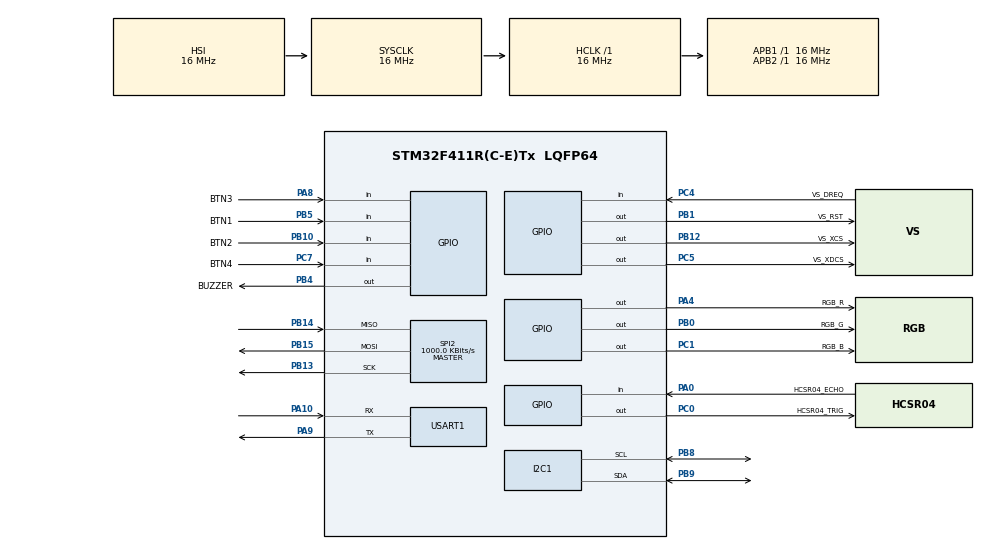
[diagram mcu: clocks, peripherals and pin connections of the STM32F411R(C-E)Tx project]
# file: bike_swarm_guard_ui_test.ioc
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Mcu.Family=STM32F4
Mcu.Name=STM32F411R(C-E)Tx
Mcu.Package=LQFP64
NVIC.PriorityGroup=NVIC_PRIORITYGROUP_4
NVIC.USART1_IRQn=true\:0\:0\:false\:false\:true\:true\:true\:true
PA0-WKUP.GPIO_Label=HCSR04_ECHO
PA0-WKUP.GPIO_PuPd=GPIO_PULLDOWN
PA0-WKUP.Signal=GPIO_Input
PA10.Mode=Asynchronous
PA10.Signal=USART1_RX
PA4.GPIO_Label=RGB_R
PA4.Signal=GPIO_Output
PA8.GPIO_Label=BTN3
PA8.GPIO_PuPd=GPIO_PULLUP
PA8.Signal=GPIO_Input
PA9.Mode=Asynchronous
PA9.Signal=USART1_TX
PB0.GPIO_Label=RGB_G
PB0.Signal=GPIO_Output
PB1.GPIO_Label=VS_RST
PB1.PinState=GPIO_PIN_SET
PB1.Signal=GPIO_Output
PB10.GPIO_Label=BTN2
PB10.GPIO_PuPd=GPIO_PULLUP
PB10.Signal=GPIO_Input
PB12.GPIO_Label=VS_XCS
PB12.PinState=GPIO_PIN_SET
PB12.Signal=GPIO_Output
PB13.Mode=Full_Duplex_Master
PB13.Signal=SPI2_SCK
PB14.Mode=Full_Duplex_Master
PB14.Signal=SPI2_MISO
PB15.Mode=Full_Duplex_Master
PB15.Signal=SPI2_MOSI
PB4.GPIO_Label=BUZZER
PB4.Signal=GPIO_Output
PB5.GPIO_Label=BTN1
PB5.GPIO_PuPd=GPIO_PULLUP
PB5.Signal=GPIO_Input
PB8.GPIO_Pu=GPIO_PULLUP
PB8.Mode=I2C
PB8.Signal=I2C1_SCL
PB9.GPIO_Pu=GPIO_PULLUP
PB9.Mode=I2C
PB9.Signal=I2C1_SDA
PC0.GPIO_Label=HCSR04_TRIG
PC0.GPIO_Speed=GPIO_SPEED_FREQ_HIGH
PC0.Signal=GPIO_Output
PC1.GPIO_Label=RGB_B
PC1.Signal=GPIO_Output
PC4.GPIO_Label=VS_DREQ
PC4.Signal=GPIO_Input
PC5.GPIO_Label=VS_XDCS
PC5.PinState=GPIO_PIN_SET
PC5.Signal=GPIO_Output
PC7.GPIO_Label=BTN4
PC7.GPIO_PuPd=GPIO_PULLUP
PC7.Signal=GPIO_Input
ProjectManager.HeapSize=0x200
ProjectManager.StackSize=0x400
ProjectManager.TargetToolchain=CMake
RCC.AHBFreq_Value=16000000
RCC.APB1Freq_Value=16000000
RCC.APB2Freq_Value=16000000
RCC.CortexFreq_Value=16000000
RCC.HSE_VALUE=25000000
RCC.HSI_VALUE=16000000
RCC.LSE_VALUE=32768
RCC.SYSCLKFreq_VALUE=16000000
RCC.VCOOutputFreq_Value=192000000
SPI2.BaudRatePrescaler=SPI_BAUDRATEPRESCALER_16
SPI2.CalculateBaudRate=1000.0 KBits/s
SPI2.Direction=SPI_DIRECTION_2LINES
SPI2.Mode=SPI_MODE_MASTER
SPI2.VirtualType=VM_MASTER
USART1.VirtualMode=VM_ASYNC
board=custom

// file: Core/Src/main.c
/* USER CODE BEGIN Header */
/**
  ******************************************************************************
  * @file           : main.c
  * @brief          : Main program body
  ******************************************************************************
  * @attention
  *
  * Copyright (c) 2026 STMicroelectronics.
  * All rights reserved.
  *
  * This software is licensed under terms that can be found in the LICENSE file
  * in the root directory of this software component.
  * If no LICENSE file comes with this software, it is provided AS-IS.
  *
  ******************************************************************************
  */
/* USER CODE END Header */
#include "main.h"

/* USER CODE BEGIN Includes */
#include "app.h"
/* USER CODE END Includes */

I2C_HandleTypeDef hi2c1;

SPI_HandleTypeDef hspi2;

UART_HandleTypeDef huart1;

void SystemClock_Config(void);
static void MX_GPIO_Init(void);
static void MX_SPI2_Init(void);
static void MX_USART1_UART_Init(void);
static void MX_I2C1_Init(void);

int main(void)
{

  /* MCU Configuration--------------------------------------------------------*/

  /* Reset of all peripherals, Initializes the Flash interface and the Systick. */
  HAL_Init();

  /* Configure the system clock */
  SystemClock_Config();

  /* Initialize all configured peripherals */
  MX_GPIO_Init();
  MX_SPI2_Init();
  MX_USART1_UART_Init();
  MX_I2C1_Init();
  /* USER CODE BEGIN 2 */
  app_init(&hspi2, &huart1);
  /* USER CODE END 2 */

  /* Infinite loop */
  while (1)
  {

    /* USER CODE BEGIN 3 */
    app_process();
  }
  /* USER CODE END 3 */
}

void SystemClock_Config(void)
{
  RCC_OscInitTypeDef RCC_OscInitStruct = {0};
  RCC_ClkInitTypeDef RCC_ClkInitStruct = {0};

  /** Configure the main internal regulator output voltage
  */
  __HAL_RCC_PWR_CLK_ENABLE();
  __HAL_PWR_VOLTAGESCALING_CONFIG(PWR_REGULATOR_VOLTAGE_SCALE1);

  /** Initializes the RCC Oscillators according to the specified parameters
  * in the RCC_OscInitTypeDef structure.
  */
  RCC_OscInitStruct.OscillatorType = RCC_OSCILLATORTYPE_HSI;
  RCC_OscInitStruct.HSIState = RCC_HSI_ON;
  RCC_OscInitStruct.HSICalibrationValue = RCC_HSICALIBRATION_DEFAULT;
  RCC_OscInitStruct.PLL.PLLState = RCC_PLL_NONE;
  if (HAL_RCC_OscConfig(&RCC_OscInitStruct) != HAL_OK)
  {
    Error_Handler();
  }

  /** Initializes the CPU, AHB and APB buses clocks
  */
  RCC_ClkInitStruct.ClockType = RCC_CLOCKTYPE_HCLK|RCC_CLOCKTYPE_SYSCLK
                              |RCC_CLOCKTYPE_PCLK1|RCC_CLOCKTYPE_PCLK2;
  RCC_ClkInitStruct.SYSCLKSource = RCC_SYSCLKSOURCE_HSI;
  RCC_ClkInitStruct.AHBCLKDivider = RCC_SYSCLK_DIV1;
  RCC_ClkInitStruct.APB1CLKDivider = RCC_HCLK_DIV1;
  RCC_ClkInitStruct.APB2CLKDivider = RCC_HCLK_DIV1;

  if (HAL_RCC_ClockConfig(&RCC_ClkInitStruct, FLASH_LATENCY_0) != HAL_OK)
  {
    Error_Handler();
  }
}

static void MX_I2C1_Init(void)
{

  hi2c1.Instance = I2C1;
  hi2c1.Init.ClockSpeed = 100000;
  hi2c1.Init.DutyCycle = I2C_DUTYCYCLE_2;
  hi2c1.Init.OwnAddress1 = 0;
  hi2c1.Init.AddressingMode = I2C_ADDRESSINGMODE_7BIT;
  hi2c1.Init.DualAddressMode = I2C_DUALADDRESS_DISABLE;
  hi2c1.Init.OwnAddress2 = 0;
  hi2c1.Init.GeneralCallMode = I2C_GENERALCALL_DISABLE;
  hi2c1.Init.NoStretchMode = I2C_NOSTRETCH_DISABLE;
  if (HAL_I2C_Init(&hi2c1) != HAL_OK)
  {
    Error_Handler();
  }

}

static void MX_SPI2_Init(void)
{

  /* SPI2 parameter configuration*/
  hspi2.Instance = SPI2;
  hspi2.Init.Mode = SPI_MODE_MASTER;
  hspi2.Init.Direction = SPI_DIRECTION_2LINES;
  hspi2.Init.DataSize = SPI_DATASIZE_8BIT;
  hspi2.Init.CLKPolarity = SPI_POLARITY_LOW;
  hspi2.Init.CLKPhase = SPI_PHASE_1EDGE;
  hspi2.Init.NSS = SPI_NSS_SOFT;
  hspi2.Init.BaudRatePrescaler = SPI_BAUDRATEPRESCALER_16;
  hspi2.Init.FirstBit = SPI_FIRSTBIT_MSB;
  hspi2.Init.TIMode = SPI_TIMODE_DISABLE;
  hspi2.Init.CRCCalculation = SPI_CRCCALCULATION_DISABLE;
  hspi2.Init.CRCPolynomial = 10;
  if (HAL_SPI_Init(&hspi2) != HAL_OK)
  {
    Error_Handler();
  }

}

static void MX_USART1_UART_Init(void)
{

  huart1.Instance = USART1;
  huart1.Init.BaudRate = 115200;
  huart1.Init.WordLength = UART_WORDLENGTH_8B;
  huart1.Init.StopBits = UART_STOPBITS_1;
  huart1.Init.Parity = UART_PARITY_NONE;
  huart1.Init.Mode = UART_MODE_TX_RX;
  huart1.Init.HwFlowCtl = UART_HWCONTROL_NONE;
  huart1.Init.OverSampling = UART_OVERSAMPLING_16;
  if (HAL_UART_Init(&huart1) != HAL_OK)
  {
    Error_Handler();
  }

}

static void MX_GPIO_Init(void)
{
  GPIO_InitTypeDef GPIO_InitStruct = {0};

  /* GPIO Ports Clock Enable */
  __HAL_RCC_GPIOC_CLK_ENABLE();
  __HAL_RCC_GPIOA_CLK_ENABLE();
  __HAL_RCC_GPIOB_CLK_ENABLE();

  /*Configure GPIO pin Output Level */
  HAL_GPIO_WritePin(GPIOC, HCSR04_TRIG_Pin|RGB_B_Pin, GPIO_PIN_RESET);

  /*Configure GPIO pin Output Level */
  HAL_GPIO_WritePin(RGB_R_GPIO_Port, RGB_R_Pin, GPIO_PIN_RESET);

  /*Configure GPIO pin Output Level */
  HAL_GPIO_WritePin(VS_XDCS_GPIO_Port, VS_XDCS_Pin, GPIO_PIN_SET);

  /*Configure GPIO pin Output Level */
  HAL_GPIO_WritePin(GPIOB, RGB_G_Pin|BUZZER_Pin, GPIO_PIN_RESET);

  /*Configure GPIO pin Output Level */
  HAL_GPIO_WritePin(GPIOB, VS_RST_Pin|VS_XCS_Pin, GPIO_PIN_SET);

  /*Configure GPIO pin : HCSR04_TRIG_Pin */
  GPIO_InitStruct.Pin = HCSR04_TRIG_Pin;
  GPIO_InitStruct.Mode = GPIO_MODE_OUTPUT_PP;
  GPIO_InitStruct.Pull = GPIO_NOPULL;
  GPIO_InitStruct.Speed = GPIO_SPEED_FREQ_HIGH;
  HAL_GPIO_Init(HCSR04_TRIG_GPIO_Port, &GPIO_InitStruct);

  /*Configure GPIO pins : RGB_B_Pin VS_XDCS_Pin */
  GPIO_InitStruct.Pin = RGB_B_Pin|VS_XDCS_Pin;
  GPIO_InitStruct.Mode = GPIO_MODE_OUTPUT_PP;
  GPIO_InitStruct.Pull = GPIO_NOPULL;
  GPIO_InitStruct.Speed = GPIO_SPEED_FREQ_LOW;
  HAL_GPIO_Init(GPIOC, &GPIO_InitStruct);

  /*Configure GPIO pin : HCSR04_ECHO_Pin */
  GPIO_InitStruct.Pin = HCSR04_ECHO_Pin;
  GPIO_InitStruct.Mode = GPIO_MODE_INPUT;
  GPIO_InitStruct.Pull = GPIO_PULLDOWN;
  HAL_GPIO_Init(HCSR04_ECHO_GPIO_Port, &GPIO_InitStruct);

  /*Configure GPIO pin : RGB_R_Pin */
  GPIO_InitStruct.Pin = RGB_R_Pin;
  GPIO_InitStruct.Mode = GPIO_MODE_OUTPUT_PP;
  GPIO_InitStruct.Pull = GPIO_NOPULL;
  GPIO_InitStruct.Speed = GPIO_SPEED_FREQ_LOW;
  HAL_GPIO_Init(RGB_R_GPIO_Port, &GPIO_InitStruct);

  /*Configure GPIO pin : VS_DREQ_Pin */
  GPIO_InitStruct.Pin = VS_DREQ_Pin;
  GPIO_InitStruct.Mode = GPIO_MODE_INPUT;
  GPIO_InitStruct.Pull = GPIO_NOPULL;
  HAL_GPIO_Init(VS_DREQ_GPIO_Port, &GPIO_InitStruct);

  /*Configure GPIO pins : RGB_G_Pin VS_RST_Pin VS_XCS_Pin BUZZER_Pin */
  GPIO_InitStruct.Pin = RGB_G_Pin|VS_RST_Pin|VS_XCS_Pin|BUZZER_Pin;
  GPIO_InitStruct.Mode = GPIO_MODE_OUTPUT_PP;
  GPIO_InitStruct.Pull = GPIO_NOPULL;
  GPIO_InitStruct.Speed = GPIO_SPEED_FREQ_LOW;
  HAL_GPIO_Init(GPIOB, &GPIO_InitStruct);

  /*Configure GPIO pins : BTN2_Pin BTN1_Pin */
  GPIO_InitStruct.Pin = BTN2_Pin|BTN1_Pin;
  GPIO_InitStruct.Mode = GPIO_MODE_INPUT;
  GPIO_InitStruct.Pull = GPIO_PULLUP;
  HAL_GPIO_Init(GPIOB, &GPIO_InitStruct);

  /*Configure GPIO pin : BTN4_Pin */
  GPIO_InitStruct.Pin = BTN4_Pin;
  GPIO_InitStruct.Mode = GPIO_MODE_INPUT;
  GPIO_InitStruct.Pull = GPIO_PULLUP;
  HAL_GPIO_Init(BTN4_GPIO_Port, &GPIO_InitStruct);

  /*Configure GPIO pin : BTN3_Pin */
  GPIO_InitStruct.Pin = BTN3_Pin;
  GPIO_InitStruct.Mode = GPIO_MODE_INPUT;
  GPIO_InitStruct.Pull = GPIO_PULLUP;
  HAL_GPIO_Init(BTN3_GPIO_Port, &GPIO_InitStruct);

}

void Error_Handler(void)
{
  __disable_irq();
  while (1)
  {
  }
}
